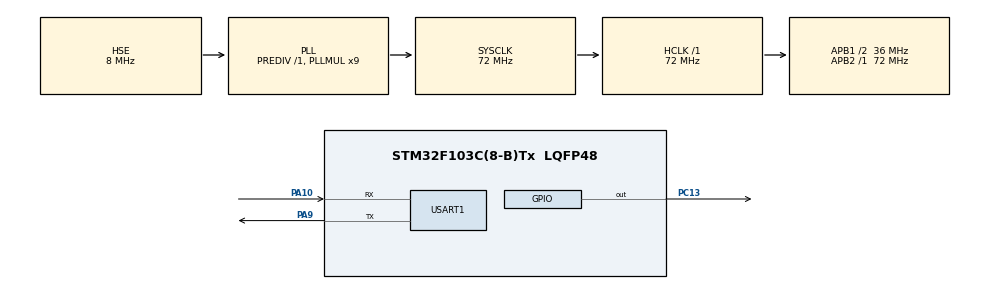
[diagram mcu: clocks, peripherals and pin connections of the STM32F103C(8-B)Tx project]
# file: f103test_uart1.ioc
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FREERTOS.Mutexes01=myMutex01,Dynamic,NULL
FREERTOS.Tasks01=defaultTask,24,128,StartDefaultTask,Default,NULL,Dynamic,NULL,NULL
Mcu.Family=STM32F1
Mcu.Name=STM32F103C(8-B)Tx
Mcu.Package=LQFP48
NVIC.PriorityGroup=NVIC_PRIORITYGROUP_4
NVIC.TIM4_IRQn=true\:15\:0\:false\:false\:true\:false\:false\:true\:true
NVIC.TimeBase=TIM4_IRQn
NVIC.TimeBaseIP=TIM4
PA10.Mode=Asynchronous
PA10.Signal=USART1_RX
PA13.Mode=Serial_Wire
PA13.Signal=SYS_JTMS-SWDIO
PA14.Mode=Serial_Wire
PA14.Signal=SYS_JTCK-SWCLK
PA9.Mode=Asynchronous
PA9.Signal=USART1_TX
PC13-TAMPER-RTC.GPIO_PuPd=GPIO_PULLUP
PC13-TAMPER-RTC.GPIO_Speed=GPIO_SPEED_FREQ_MEDIUM
PC13-TAMPER-RTC.Signal=GPIO_Output
PC14-OSC32_IN.Mode=LSE-External-Oscillator
PC14-OSC32_IN.Signal=RCC_OSC32_IN
PC15-OSC32_OUT.Mode=LSE-External-Oscillator
PC15-OSC32_OUT.Signal=RCC_OSC32_OUT
PD0-OSC_IN.Mode=HSE-External-Oscillator
PD0-OSC_IN.Signal=RCC_OSC_IN
PD1-OSC_OUT.Mode=HSE-External-Oscillator
PD1-OSC_OUT.Signal=RCC_OSC_OUT
ProjectManager.HeapSize=0x200
ProjectManager.StackSize=0x400
ProjectManager.TargetToolchain=Makefile
RCC.AHBFreq_Value=72000000
RCC.APB1CLKDivider=RCC_HCLK_DIV2
RCC.APB1Freq_Value=36000000
RCC.APB1TimFreq_Value=72000000
RCC.APB2Freq_Value=72000000
RCC.APB2TimFreq_Value=72000000
RCC.HCLKFreq_Value=72000000
RCC.PLLMUL=RCC_PLL_MUL9
RCC.PLLSourceVirtual=RCC_PLLSOURCE_HSE
RCC.SYSCLKFreq_VALUE=72000000
RCC.SYSCLKSource=RCC_SYSCLKSOURCE_PLLCLK
RCC.USBFreq_Value=72000000
TIM1.AutoReloadPreload=TIM_AUTORELOAD_PRELOAD_ENABLE
USART1.VirtualMode=VM_ASYNC
VP_FREERTOS_VS_CMSIS_V2.Mode=CMSIS_V2
VP_SYS_VS_tim4.Mode=TIM4
VP_TIM1_VS_ClockSourceINT.Mode=Internal
board=custom

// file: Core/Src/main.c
/* USER CODE BEGIN Header */
/**
 ******************************************************************************
 * @file           : main.c
 * @brief          : Main program body
 ******************************************************************************
 * @attention
 *
 * Copyright (c) 2022 STMicroelectronics.
 * All rights reserved.
 *
 * This software is licensed under terms that can be found in the LICENSE file
 * in the root directory of this software component.
 * If no LICENSE file comes with this software, it is provided AS-IS.
 *
 ******************************************************************************
 */
#include "MultiButton.h"
/* USER CODE END Header */
#include "main.h"
#include "cmsis_os.h"
#include "tim.h"
#include "usart.h"
#include "gpio.h"

/* USER CODE BEGIN PV */
struct Button button1;
/* USER CODE END PV */

void SystemClock_Config(void);
void MX_FREERTOS_Init(void);

/* USER CODE BEGIN 0 */
void pressDownCallback(void *p)
{
  static int i = 0;
  HAL_GPIO_TogglePin(GPIOC, GPIO_PIN_13);
  printf("button press down. %d\r\n", i);
  i++;
}

uint8_t readPinLevel()
{
  return HAL_GPIO_ReadPin(GPIOA, GPIO_PIN_0);
}
/* USER CODE END 0 */

int main(void)
{

  /* MCU Configuration--------------------------------------------------------*/

  /* Reset of all peripherals, Initializes the Flash interface and the Systick. */
  HAL_Init();

  /* Configure the system clock */
  SystemClock_Config();

  /* Initialize all configured peripherals */
  MX_GPIO_Init();
  MX_USART1_UART_Init();
  MX_TIM1_Init();
  /* USER CODE BEGIN 2 */
  button_init(&button1, readPinLevel, 1);
  button_attach(&button1, PRESS_DOWN, pressDownCallback);
  button_start(&button1);
  /* USER CODE END 2 */

  /* Init scheduler */
  osKernelInitialize();  /* Call init function for freertos objects (in freertos.c) */
  MX_FREERTOS_Init();

  /* Start scheduler */
  osKernelStart();

  /* We should never get here as control is now taken by the scheduler */
  /* Infinite loop */
  /* USER CODE BEGIN WHILE */
  while (1)
  {
    HAL_Delay(5);
    button_ticks();
    /* USER CODE END WHILE */

  }
}

void SystemClock_Config(void)
{
  RCC_OscInitTypeDef RCC_OscInitStruct = {0};
  RCC_ClkInitTypeDef RCC_ClkInitStruct = {0};

  /** Initializes the RCC Oscillators according to the specified parameters
  * in the RCC_OscInitTypeDef structure.
  */
  RCC_OscInitStruct.OscillatorType = RCC_OSCILLATORTYPE_HSE;
  RCC_OscInitStruct.HSEState = RCC_HSE_ON;
  RCC_OscInitStruct.HSEPredivValue = RCC_HSE_PREDIV_DIV1;
  RCC_OscInitStruct.HSIState = RCC_HSI_ON;
  RCC_OscInitStruct.PLL.PLLState = RCC_PLL_ON;
  RCC_OscInitStruct.PLL.PLLSource = RCC_PLLSOURCE_HSE;
  RCC_OscInitStruct.PLL.PLLMUL = RCC_PLL_MUL9;
  if (HAL_RCC_OscConfig(&RCC_OscInitStruct) != HAL_OK)
  {
    Error_Handler();
  }

  /** Initializes the CPU, AHB and APB buses clocks
  */
  RCC_ClkInitStruct.ClockType = RCC_CLOCKTYPE_HCLK|RCC_CLOCKTYPE_SYSCLK
                              |RCC_CLOCKTYPE_PCLK1|RCC_CLOCKTYPE_PCLK2;
  RCC_ClkInitStruct.SYSCLKSource = RCC_SYSCLKSOURCE_PLLCLK;
  RCC_ClkInitStruct.AHBCLKDivider = RCC_SYSCLK_DIV1;
  RCC_ClkInitStruct.APB1CLKDivider = RCC_HCLK_DIV2;
  RCC_ClkInitStruct.APB2CLKDivider = RCC_HCLK_DIV1;

  if (HAL_RCC_ClockConfig(&RCC_ClkInitStruct, FLASH_LATENCY_2) != HAL_OK)
  {
    Error_Handler();
  }
}

void HAL_TIM_PeriodElapsedCallback(TIM_HandleTypeDef *htim)
{
  if (htim->Instance == TIM4) {
    HAL_IncTick();
  }
}

void Error_Handler(void)
{
  __disable_irq();
  while (1)
  {
  }
}

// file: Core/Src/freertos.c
/* USER CODE BEGIN Header */
/**
  ******************************************************************************
  * File Name          : freertos.c
  * Description        : Code for freertos applications
  ******************************************************************************
  * @attention
  *
  * Copyright (c) 2022 STMicroelectronics.
  * All rights reserved.
  *
  * This software is licensed under terms that can be found in the LICENSE file
  * in the root directory of this software component.
  * If no LICENSE file comes with this software, it is provided AS-IS.
  *
  ******************************************************************************
  */
/* USER CODE END Header */

#include "FreeRTOS.h"
#include "task.h"
#include "main.h"
#include "cmsis_os.h"
#include "semphr.h"
#include "usart.h"
#include "queue.h"

/* USER CODE BEGIN Variables */
osThreadId_t ledTaskHandle;
const osThreadAttr_t ledTask_attributes =
{
  .name = "ledTask",
  .stack_size = 128 * 4,
  .priority = (osPriority_t) osPriorityNormal,
};
/* USER CODE END Variables */
/* Definitions for defaultTask */
osThreadId_t defaultTaskHandle;
const osThreadAttr_t defaultTask_attributes = {
  .name = "defaultTask",
  .stack_size = 128 * 4,
  .priority = (osPriority_t) osPriorityNormal,
};
/* Definitions for myMutex01 */
/* USER CODE BEGIN FunctionPrototypes */
void ledTaskFunction(void * arg);
void myTask03(void *arg);
TaskHandle_t task03Handle;
QueueHandle_t myQueueHandle;
typedef struct myMessage
{
  uint8_t messageID;
  char data[40];
}myMessage_or;
#define QUEUELENTH 5
/* USER CODE END FunctionPrototypes */

void StartDefaultTask(void *argument);

void MX_FREERTOS_Init(void); /* (MISRA C 2004 rule 8.1) */

void MX_FREERTOS_Init(void) {
  /* Create the mutex(es) */
  /* creation of myMutex01 */

  /* USER CODE BEGIN RTOS_QUEUES */
  /* add queues, ... */
  myQueueHandle = xQueueCreate(5, sizeof(myMessage_or));
  /* USER CODE END RTOS_QUEUES */

  /* Create the thread(s) */
  /* creation of defaultTask */
  //xTaskCreate(myTask03, "task 03", 128 * 4, (void *)myQueueHandle, osPriorityNormal, &task03Handle);

  defaultTaskHandle = osThreadNew(StartDefaultTask, NULL, &defaultTask_attributes);

  /* USER CODE BEGIN RTOS_THREADS */
  /* add threads, ... */
  ledTaskHandle = osThreadNew(ledTaskFunction, NULL, &ledTask_attributes);

  /* USER CODE END RTOS_THREADS */

  /* USER CODE BEGIN RTOS_EVENTS */

  if(myQueueHandle == NULL)
    printf("myQueue create faild.\r\n");
  else
    printf("myQueue create seccess.\r\n");
  printf("end of the initation.\r\n");
  /* add events, ... */
  /* USER CODE END RTOS_EVENTS */

}

void StartDefaultTask(void *argument)
{
  /* USER CODE BEGIN StartDefaultTask */
  struct myMessage queueMessage1 = {.messageID = 1, .data = "Hello world!\r\n"};
  struct myMessage queueMessage2 = {.messageID = 2, .data = "Nothing in the world can take12345678\r\n"};
  /* Infinite loop */
  for(;;)
  {
    if(xQueueSend(myQueueHandle, &queueMessage1, 100) == pdTRUE)
      ;
    else
      printf("Queue is full.\r\n");
    if(xQueueSend(myQueueHandle, &queueMessage2, 100) == pdTRUE)
      ;
    else
      printf("Queue is full.\r\n");
    if(xQueueSend(myQueueHandle, " can you do this\r\n", 100) == pdTRUE)
      ;
    else
      printf("Queue is full.\r\n");
    if(xQueueSend(myQueueHandle, " message 3\r\n", 100) == pdTRUE)
      ;
    else
      printf("Queue is full.\r\n");
    if(xQueueSend(myQueueHandle, " Message 4\r\n", 100) == pdTRUE)
      ;
    else
      printf("Queue is full.\r\n");
    osDelay(500);
  }
  /* USER CODE END StartDefaultTask */
}

/* USER CODE BEGIN Application */
void ledTaskFunction(void * arg)
{
  struct myMessage messageVector;
  while (1)
  {
    HAL_GPIO_TogglePin(GPIOC, GPIO_PIN_13);
    if(xQueueReceive(myQueueHandle, &messageVector, portMAX_DELAY) == pdTRUE)
      {
        printf("%s",messageVector.data);
      }
    else
      printf("receive faild.\r\n");
  }
}

/* USER CODE END Application */
